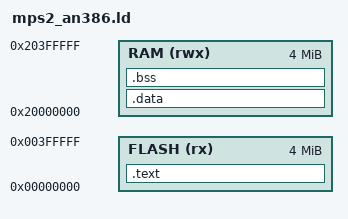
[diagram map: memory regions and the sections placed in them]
/*
 * Minimal linker script for MPS2-AN386 (Cortex-M4) under QEMU.
 * QEMU boots Cortex-M by reading the initial SP from 0x0 and the
 * reset vector from 0x4, so .isr_vector must land at the flash origin.
 */

MEMORY
{
    FLASH (rx)  : ORIGIN = 0x00000000, LENGTH = 4M
    RAM   (rwx) : ORIGIN = 0x20000000, LENGTH = 4M
}

_stack_top = ORIGIN(RAM) + LENGTH(RAM);

SECTIONS
{
    .text :
    {
        KEEP(*(.isr_vector))
        *(.text*)
        *(.rodata*)
        . = ALIGN(4);
        _etext = .;
    } > FLASH

    .data : AT(_etext)
    {
        _sdata = .;
        *(.data*)
        . = ALIGN(4);
        _edata = .;
    } > RAM

    .bss :
    {
        _sbss = .;
        *(.bss*)
        *(COMMON)
        . = ALIGN(4);
        _ebss = .;
    } > RAM

    _end = .;
    _heap_start = _end;
}
